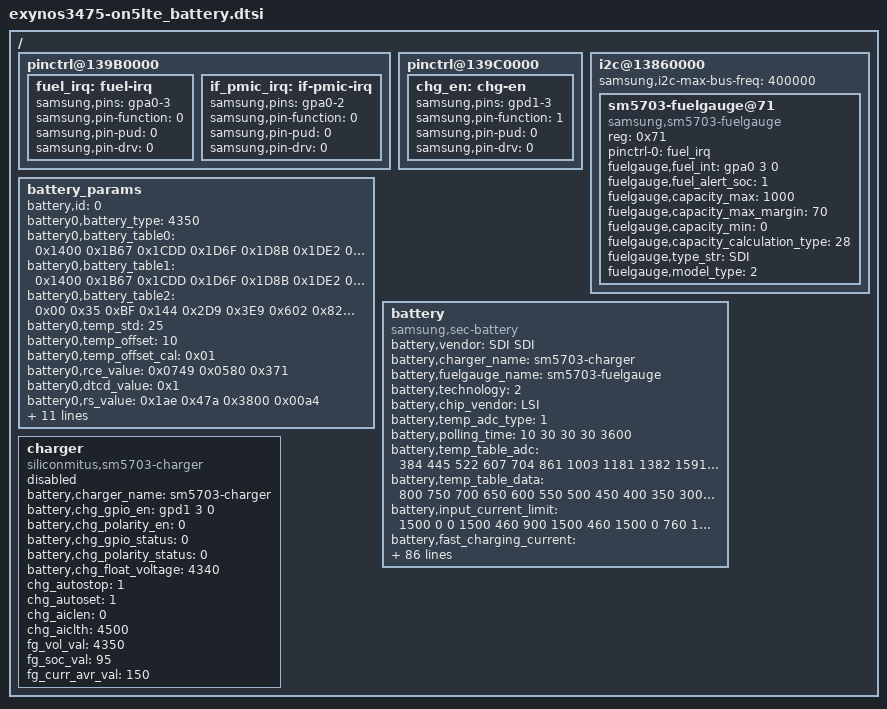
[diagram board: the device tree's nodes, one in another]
/*
 * SAMSUNG UNIVERSAL3475 board device tree source
 *
 * Copyright (c) 2015 Samsung Electronics Co., Ltd.
 *		http://www.samsung.com
 *
 * This program is free software; you can redistribute it and/or modify
 * it under the terms of the GNU General Public License version 2 as
 * published by the Free Software Foundation.
*/

/ {
	pinctrl@139B0000 {
		fuel_irq: fuel-irq {
			samsung,pins = "gpa0-3";
			samsung,pin-function = <0>;
			samsung,pin-pud = <0>;
			samsung,pin-drv = <0>;
		};
	};

	pinctrl@139B0000 {
		if_pmic_irq: if-pmic-irq {
			samsung,pins = "gpa0-2";
			samsung,pin-function = <0>;
			samsung,pin-pud = <0>;
			samsung,pin-drv = <0>;
		};
	};

	pinctrl@139C0000 {
		chg_en: chg-en {
			samsung,pins = "gpd1-3";
			samsung,pin-function = <1>;
			samsung,pin-pud = <0>;
			samsung,pin-drv = <0>;
		};
	};

	i2c@13860000 {
		status = "okay";
		samsung,i2c-max-bus-freq = <400000>;
		sm5703-fuelgauge@71 {
			compatible = "samsung,sm5703-fuelgauge";
			reg = <0x71>;
			pinctrl-names = "default";
			pinctrl-0 = <&fuel_irq>;
			fuelgauge,fuel_int = <&gpa0 3 0>;
			fuelgauge,fuel_alert_soc = <1>;
			fuelgauge,capacity_max = <1000>;
			fuelgauge,capacity_max_margin = <70>;
			fuelgauge,capacity_min = <0>;
			fuelgauge,capacity_calculation_type = <28>;
			fuelgauge,type_str = "SDI";
			fuelgauge,model_type = <2>;
		};
	};

	battery_params {
		battery,id = <0>; /* -1 means auto, detected by F/G */
		battery0,battery_type = <4350>; /* 4200 4350 4400 */
		battery0,battery_table0 = <0x1400 0x1B67 0x1CDD 0x1D6F 0x1D8B 0x1DE2 0x1E32 0x1E63 0x1EAB 0x1EDF 0x1F06 0x1F54 0x1FC5 0x20A0 0x2261 0x2399>;
		battery0,battery_table1 = <0x1400 0x1B67 0x1CDD 0x1D6F 0x1D8B 0x1DE2 0x1E32 0x1E63 0x1EAB 0x1EDF 0x1F06 0x1F54 0x1FC5 0x20A0 0x2261 0x2399>;
		battery0,battery_table2 = <0x00 0x35 0xBF 0x144 0x2D9 0x3E9 0x602 0x821 0xA3B 0xB4B 0xBD5 0xC5A 0xDEF 0x1093 0x14CC 0x14DC>;
		battery0,temp_std = <25>;
		battery0,temp_offset = <10>;
		battery0,temp_offset_cal = <0x01>;
		battery0,rce_value = <0x0749 0x0580 0x371>;
		battery0,dtcd_value = <0x1>;
		battery0,rs_value = <0x1ae 0x47a 0x3800 0x00a4>; /*rs mix_factor max min*/
		battery0,vit_period = <0x3506>;
		battery0,mix_value = <0x0503 0x0004>; /*mix_rate init_blank*/
		battery0,topoff_soc = <0x0 0x5>; /*enable soc*/
		battery0,tem_poff = <3400 50 3350 50>;
		battery0,charge_offset_cal = <0x03>;
		battery0,min_charge_curr = <200>;
		battery0,volt_cal = <0x809E>;
		battery0,curr_cal = <0x7485>;
		battery0,ext_temp_cal = <0 10 1 1 1 7 1 2>;
		battery0,v_alarm = <3250>;
		battery0,data_ver = <0x01>;
	};

	battery {
		status = "okay";

		pinctrl-names = "default";

		compatible = "samsung,sec-battery";
		battery,vendor = "SDI SDI";
		battery,charger_name = "sm5703-charger";
		battery,fuelgauge_name = "sm5703-fuelgauge";
		battery,technology = <2>; /* POWER_SUPPLY_TECHNOLOGY_LION */
		/* .temp_cohot = -1000; */
		/* .temp_cocold = -4325; */

		battery,chip_vendor = "LSI";
		battery,temp_adc_type = <1>; /* SEC_BATTERY_ADC_TYPE_AP */

		battery,polling_time = <10 30 30 30 3600>;

		battery,temp_table_adc = <384 445 522 607 704 861 1003 1181 1382 1591 1762 1988 2295 
								2554 2772 2988 3162 3331 3479 3611 3731>;

		battery,temp_table_data = <800 750 700 650 600 550 500 450 400 350 300 250 200
								150 100 50 0 (-50) (-100) (-150) (-200)>;

		battery,input_current_limit = <1500 0 0 1500 460 900 1500 460 1500 0 760 1500 1500 0 1500 400 700 1500 300 1500 1500 0 1500 1500 1500 80 1500 1500 1500 450>;
		battery,fast_charging_current = <2000 0 0 2000 460 2000 2000 460 2000 0 2000 2000 2000 0 2000 400 2000 2000 300 2000 2000 0 2000 2000 2000 80 2000 2000 2000 450>;
		battery,full_check_current_1st = <150 0 0 150 150 150 150 150 150 0 150 150 150 0 0 150 150 150 150 150 150 0 150 150 150 0 150 150 150 150>;
		battery,full_check_current_2nd = <100 0 0 100 100 100 100 100 100 0 100 100 100 0 0 100 100 100 100 100 100 0 100 100 100 0 100 100 100 100>;
		battery,high_full_check_current_1st = <150 0 0 150 150 150 150 150 150 0 150 150 150 0 0 150 150 150 150 150 150 0 150 150 150 0 150 150 150 150>;
		battery,high_full_check_current_2nd = <150 0 0 150 150 150 150 150 150 0 150 150 150 0 0 150 150 150 150 150 150 0 150 150 150 0 150 150 150 150>;
		battery,low_full_check_current_1st = <150 0 0 150 150 150 150 150 150 0 150 150 150 0 0 150 150 150 150 150 150 0 150 150 150 0 150 150 150 150>;
		battery,low_full_check_current_2nd = <150 0 0 150 150 150 150 150 150 0 150 150 150 0 0 150 150 150 150 150 150 0 150 150 150 0 150 150 150 150>;

		battery,adc_check_count = <5>;

		battery,cable_check_type = <4>; /* SEC_BATTERY_CABLE_CHECK_PSY */
		battery,cable_source_type = <1>; /* SEC_BATTERY_CABLE_SOURCE_EXTERNAL */
		battery,event_waiting_time = <600>;
		battery,polling_type = <1>; /* SEC_BATTERY_MONITOR_ALARM */
		battery,monitor_initial_count = <0>;

		battery,battery_check_type = <6>; /* SEC_BATTERY_CHECK_INT */
		battery,check_count = <0>;
		battery,bat_irq_gpio = <&gpa0 5 0>;
		battery,bat_irq_attr = <0x00002003>; /*  IRQF_TRIGGER_RISING	0x00000001
							 IRQF_TRIGGER_FALLING	0x00000002
							 IRQF_ONESHOT		0x00002000
							*/
		battery,check_adc_max = <1440>;
		battery,check_adc_min = <0>;

		battery,ovp_uvlo_check_type = <3>; /* SEC_BATTERY_OVP_UVLO_CHGPOLLING */

		battery,thermal_source = <2>; /* SEC_BATTERY_THERMAL_SOURCE_ADC */

		battery,temp_check_type = <2>; /* SEC_BATTERY_TEMP_CHECK_TEMP */
		battery,temp_check_count = <1>;
		battery,temp_highlimit_threshold_event = <800>;
		battery,temp_highlimit_recovery_event = <750>;
		battery,temp_high_threshold_event = <550>;
		battery,temp_high_recovery_event = <500>;
		battery,temp_low_threshold_event = <(-50)>;
		battery,temp_low_recovery_event = <0>;
		battery,temp_highlimit_threshold_normal = <800>;
		battery,temp_highlimit_recovery_normal = <750>;
		battery,temp_high_threshold_normal = <550>;
		battery,temp_high_recovery_normal = <500>;
		battery,temp_low_threshold_normal = <(-50)>;
		battery,temp_low_recovery_normal = <0>;
		battery,temp_highlimit_threshold_lpm = <800>;
		battery,temp_highlimit_recovery_lpm = <750>;
		battery,temp_high_threshold_lpm = <550>;
		battery,temp_high_recovery_lpm = <500>;
		battery,temp_low_threshold_lpm = <(-50)>;
		battery,temp_low_recovery_lpm = <0>;

		battery,full_check_type = <7>; /* SEC_BATTERY_FULLCHARGED_CHGPSY */
		battery,full_check_type_2nd = <7>; /* SEC_BATTERY_FULLCHARGED_CHGPSY */
		battery,full_check_count = <1>;
		battery,chg_gpio_full_check = <0>;
		battery,chg_polarity_full_check = <1>;

		/* SEC_BATTERY_FULL_CONDITION_SOC |
		   SEC_BATTERY_FULL_CONDITION_NOTIMEFULL |
		   SEC_BATTERY_FULL_CONDITION_VCELL */
		battery,full_condition_type = <15>;
		battery,full_condition_soc = <93>;
		battery,full_condition_vcell = <4250>;

		battery,recharge_check_count = <2>;
		battery,recharge_condition_type = <4>; /* SEC_BATTERY_RECHARGE_CONDITION_VCELL */
		battery,recharge_condition_soc = <98>;
		battery,recharge_condition_vcell = <4290>;

		battery,charging_total_time = <21600>;
		battery,recharging_total_time = <5400>;
		battery,charging_reset_time = <0>;

		battery,always_enable;

		io-channels = <&exynos_adc 0>;
		io-channel-names = "adc-temp";
		#io-channel-cells = <1>;
		io-channel-ranges;

		battery,chg_float_voltage = <4340>;

		battery,self_discharging_en;
		battery,force_discharging_limit = <650>;
		battery,force_discharging_recov = <550>;
		battery,self_discharging_voltage_limit = <4250>;
		battery,discharging_adc_max = <2600>;
		battery,discharging_adc_min = <1700>;
		battery,discharging_ntc_limit = <2750>;

		battery,self_discharging_temp_block = <600>;
		battery,self_discharging_volt_block = <4250>;
		battery,self_discharging_temp_recov = <550>;
		battery,self_discharging_temp_pollingtime = <400>;

		battery,swelling_high_temp_block = <500>;
		battery,swelling_high_temp_recov = <450>;
		battery,swelling_low_temp_block = <50>;
		battery,swelling_low_temp_recov = <100>;
		battery,swelling_chg_current = <1300>;
		battery,swelling_chg_high_current = <1500>;
		battery,swelling_drop_float_voltage = <4200>;
		battery,swelling_high_rechg_voltage = <4150>;
		battery,swelling_low_rechg_voltage = <4050>;
	};

	charger {
		status = "disable";
		compatible = "siliconmitus,sm5703-charger";

		/* Charger */
		battery,charger_name = "sm5703-charger";
		battery,chg_gpio_en = <&gpd1 3 0>;
		battery,chg_polarity_en = <0>;
		battery,chg_gpio_status = <0>;
		battery,chg_polarity_status = <0>;
		battery,chg_float_voltage = <4340>;
		chg_autostop = <1>;
		chg_autoset = <1>;
		chg_aiclen = <0>;
		chg_aiclth = <4500>;
		fg_vol_val = <4350>;
		fg_soc_val = <95>;
		fg_curr_avr_val = <150>;
	};
};
